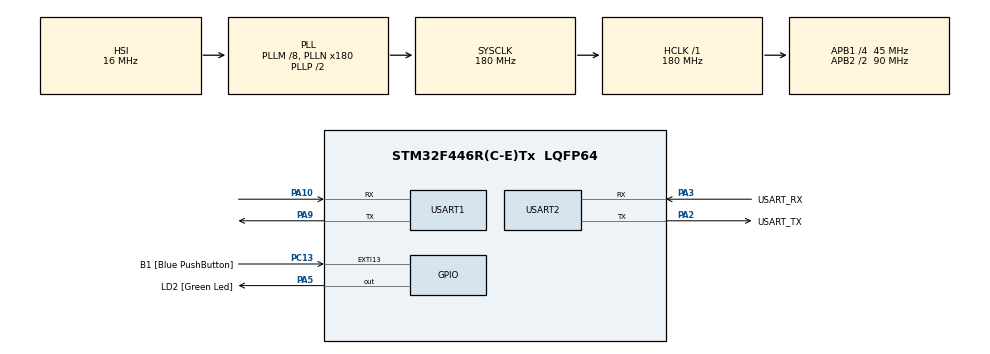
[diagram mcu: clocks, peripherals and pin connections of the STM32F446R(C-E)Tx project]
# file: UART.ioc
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Dma.Request0=USART1_RX
Dma.Request1=USART1_TX
Dma.Request2=USART2_RX
Dma.Request3=USART2_TX
Dma.USART1_RX.0.Direction=DMA_PERIPH_TO_MEMORY
Dma.USART1_RX.0.FIFOMode=DMA_FIFOMODE_DISABLE
Dma.USART1_RX.0.Instance=DMA2_Stream2
Dma.USART1_RX.0.MemDataAlignment=DMA_MDATAALIGN_BYTE
Dma.USART1_RX.0.MemInc=DMA_MINC_ENABLE
Dma.USART1_RX.0.Mode=DMA_CIRCULAR
Dma.USART1_RX.0.PeriphDataAlignment=DMA_PDATAALIGN_BYTE
Dma.USART1_RX.0.PeriphInc=DMA_PINC_DISABLE
Dma.USART1_RX.0.Priority=DMA_PRIORITY_LOW
Dma.USART1_TX.1.Direction=DMA_MEMORY_TO_PERIPH
Dma.USART1_TX.1.FIFOMode=DMA_FIFOMODE_DISABLE
Dma.USART1_TX.1.Instance=DMA2_Stream7
Dma.USART1_TX.1.MemDataAlignment=DMA_MDATAALIGN_BYTE
Dma.USART1_TX.1.MemInc=DMA_MINC_ENABLE
Dma.USART1_TX.1.Mode=DMA_NORMAL
Dma.USART1_TX.1.PeriphDataAlignment=DMA_PDATAALIGN_BYTE
Dma.USART1_TX.1.PeriphInc=DMA_PINC_DISABLE
Dma.USART1_TX.1.Priority=DMA_PRIORITY_LOW
Dma.USART2_RX.2.Direction=DMA_PERIPH_TO_MEMORY
Dma.USART2_RX.2.FIFOMode=DMA_FIFOMODE_DISABLE
Dma.USART2_RX.2.Instance=DMA1_Stream5
Dma.USART2_RX.2.MemDataAlignment=DMA_MDATAALIGN_BYTE
Dma.USART2_RX.2.MemInc=DMA_MINC_ENABLE
Dma.USART2_RX.2.Mode=DMA_CIRCULAR
Dma.USART2_RX.2.PeriphDataAlignment=DMA_PDATAALIGN_BYTE
Dma.USART2_RX.2.PeriphInc=DMA_PINC_DISABLE
Dma.USART2_RX.2.Priority=DMA_PRIORITY_LOW
Dma.USART2_TX.3.Direction=DMA_MEMORY_TO_PERIPH
Dma.USART2_TX.3.FIFOMode=DMA_FIFOMODE_DISABLE
Dma.USART2_TX.3.Instance=DMA1_Stream6
Dma.USART2_TX.3.MemDataAlignment=DMA_MDATAALIGN_BYTE
Dma.USART2_TX.3.MemInc=DMA_MINC_ENABLE
Dma.USART2_TX.3.Mode=DMA_NORMAL
Dma.USART2_TX.3.PeriphDataAlignment=DMA_PDATAALIGN_BYTE
Dma.USART2_TX.3.PeriphInc=DMA_PINC_DISABLE
Dma.USART2_TX.3.Priority=DMA_PRIORITY_LOW
FREERTOS.CountingSemaphores01=uartTxSem,1,Dynamic,NULL,0
FREERTOS.Mutexes01=uartTxMutex,Dynamic,NULL,Available;logMutex,Dynamic,NULL,Available;rtcMutex,Dynamic,NULL,Available;flashMutex,Dynamic,NULL,Available
FREERTOS.Queues01=uartRxQueue,8,FEB_UART_RxQueueMsg_t,0,Dynamic,NULL,NULL
FREERTOS.Tasks01=flashTask,24,2048,StartFlashTask,As weak,NULL,Dynamic,NULL,NULL;uartRxTask,16,2048,StartUARTRxTask,As weak,NULL,Dynamic,NULL,NULL
FREERTOS.configENABLE_FPU=1
FREERTOS.configTOTAL_HEAP_SIZE=51200
Mcu.Family=STM32F4
Mcu.Name=STM32F446R(C-E)Tx
Mcu.Package=LQFP64
NVIC.DMA1_Stream5_IRQn=true\:5\:0\:false\:false\:true\:true\:false\:true\:true
NVIC.DMA1_Stream6_IRQn=true\:5\:0\:false\:false\:true\:true\:false\:true\:true
NVIC.DMA2_Stream2_IRQn=true\:5\:0\:false\:false\:true\:true\:false\:true\:true
NVIC.DMA2_Stream7_IRQn=true\:5\:0\:false\:false\:true\:true\:false\:true\:true
NVIC.PriorityGroup=NVIC_PRIORITYGROUP_4
NVIC.RTC_Alarm_IRQn=true\:5\:0\:false\:false\:true\:true\:true\:true\:true
NVIC.TIM8_TRG_COM_TIM14_IRQn=true\:15\:0\:false\:false\:true\:false\:false\:true\:true
NVIC.TimeBase=TIM8_TRG_COM_TIM14_IRQn
NVIC.TimeBaseIP=TIM14
NVIC.USART1_IRQn=true\:5\:0\:false\:false\:true\:true\:true\:true\:true
NVIC.USART2_IRQn=true\:5\:0\:false\:false\:true\:true\:true\:true\:true
PA10.Mode=Asynchronous
PA10.Signal=USART1_RX
PA13.GPIO_Label=TMS
PA13.Mode=Trace_Asynchronous_SW
PA13.Signal=SYS_JTMS-SWDIO
PA14.GPIO_Label=TCK
PA14.Mode=Trace_Asynchronous_SW
PA14.Signal=SYS_JTCK-SWCLK
PA2.GPIO_Label=USART_TX
PA2.Mode=Asynchronous
PA2.Signal=USART2_TX
PA3.GPIO_Label=USART_RX
PA3.Mode=Asynchronous
PA3.Signal=USART2_RX
PA5.GPIO_Label=LD2 [Green Led]
PA5.Signal=GPIO_Output
PA9.Mode=Asynchronous
PA9.Signal=USART1_TX
PB3.GPIO_Label=SWO
PB3.Mode=Trace_Asynchronous_SW
PB3.Signal=SYS_JTDO-SWO
PC13.GPIO_Label=B1 [Blue PushButton]
PC13.GPIO_ModeDefaultEXTI=GPIO_MODE_IT_FALLING
PC13.Signal=GPXTI13
PC14-OSC32_IN.Mode=LSE-External-Oscillator
PC14-OSC32_IN.Signal=RCC_OSC32_IN
PC15-OSC32_OUT.Mode=LSE-External-Oscillator
PC15-OSC32_OUT.Signal=RCC_OSC32_OUT
ProjectManager.HeapSize=0x200
ProjectManager.StackSize=0x400
ProjectManager.TargetToolchain=CMake
RCC.48MHZClocksFreq_Value=84000000
RCC.AHBFreq_Value=180000000
RCC.APB1CLKDivider=RCC_HCLK_DIV4
RCC.APB1Freq_Value=45000000
RCC.APB1TimFreq_Value=90000000
RCC.APB2CLKDivider=RCC_HCLK_DIV2
RCC.APB2Freq_Value=90000000
RCC.APB2TimFreq_Value=180000000
RCC.CortexFreq_Value=180000000
RCC.FLatency-AdvancedSettings=FLASH_LATENCY_5
RCC.HCLKFreq_Value=180000000
RCC.HSE_VALUE=8000000
RCC.HSI_VALUE=16000000
RCC.PLLM=8
RCC.PLLN=180
RCC.SYSCLKFreq_VALUE=180000000
RCC.SYSCLKSource=RCC_SYSCLKSOURCE_PLLCLK
RCC.USBFreq_Value=180000000
RCC.VCOOutputFreq_Value=360000000
RTC.Alarm=RTC_ALARM_A
USART1.VirtualMode=VM_ASYNC
USART2.VirtualMode=VM_ASYNC
VP_FREERTOS_VS_CMSIS_V2.Mode=CMSIS_V2
VP_RTC_VS_RTC_Activate.Mode=RTC_Enabled
VP_RTC_VS_RTC_Alarm_A_Intern.Mode=Alarm A
VP_RTC_VS_RTC_Calendar.Mode=RTC_Calendar
VP_SYS_VS_tim14.Mode=TIM14
board=NUCLEO-F446RE

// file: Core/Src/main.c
/* USER CODE BEGIN Header */
/**
  ******************************************************************************
  * @file           : main.c
  * @brief          : Main program body
  ******************************************************************************
  * @attention
  *
  * Copyright (c) 2026 STMicroelectronics.
  * All rights reserved.
  *
  * This software is licensed under terms that can be found in the LICENSE file
  * in the root directory of this software component.
  * If no LICENSE file comes with this software, it is provided AS-IS.
  *
  ******************************************************************************
  */
/* USER CODE END Header */
#include "main.h"
#include "cmsis_os.h"
#include "dma.h"
#include "rtc.h"
#include "usart.h"
#include "gpio.h"

void SystemClock_Config(void);
void MX_FREERTOS_Init(void);

int main(void)
{

  /* MCU Configuration--------------------------------------------------------*/

  /* Reset of all peripherals, Initializes the Flash interface and the Systick. */
  HAL_Init();

  /* Configure the system clock */
  SystemClock_Config();

  /* Initialize all configured peripherals */
  MX_GPIO_Init();
  MX_DMA_Init();
  MX_RTC_Init();
  MX_USART1_UART_Init();
  MX_USART2_UART_Init();

  /* Init scheduler */
  osKernelInitialize();  /* Call init function for freertos objects (in cmsis_os2.c) */
  MX_FREERTOS_Init();

  /* Start scheduler */
  osKernelStart();

  /* We should never get here as control is now taken by the scheduler */

  /* Infinite loop */
  while (1)
  {

  }
}

void SystemClock_Config(void)
{
  RCC_OscInitTypeDef RCC_OscInitStruct = {0};
  RCC_ClkInitTypeDef RCC_ClkInitStruct = {0};

  /** Configure the main internal regulator output voltage
  */
  __HAL_RCC_PWR_CLK_ENABLE();
  __HAL_PWR_VOLTAGESCALING_CONFIG(PWR_REGULATOR_VOLTAGE_SCALE1);

  /** Initializes the RCC Oscillators according to the specified parameters
  * in the RCC_OscInitTypeDef structure.
  */
  RCC_OscInitStruct.OscillatorType = RCC_OSCILLATORTYPE_HSI|RCC_OSCILLATORTYPE_LSI;
  RCC_OscInitStruct.LSEState = RCC_LSE_ON;
  RCC_OscInitStruct.HSIState = RCC_HSI_ON;
  RCC_OscInitStruct.HSICalibrationValue = RCC_HSICALIBRATION_DEFAULT;
  RCC_OscInitStruct.LSIState = RCC_LSI_ON;
  RCC_OscInitStruct.PLL.PLLState = RCC_PLL_ON;
  RCC_OscInitStruct.PLL.PLLSource = RCC_PLLSOURCE_HSI;
  RCC_OscInitStruct.PLL.PLLM = 8;
  RCC_OscInitStruct.PLL.PLLN = 180;
  RCC_OscInitStruct.PLL.PLLP = RCC_PLLP_DIV2;
  RCC_OscInitStruct.PLL.PLLQ = 2;
  RCC_OscInitStruct.PLL.PLLR = 2;
  if (HAL_RCC_OscConfig(&RCC_OscInitStruct) != HAL_OK)
  {
    Error_Handler();
  }

  /** Activate the Over-Drive mode
  */
  if (HAL_PWREx_EnableOverDrive() != HAL_OK)
  {
    Error_Handler();
  }

  /** Initializes the CPU, AHB and APB buses clocks
  */
  RCC_ClkInitStruct.ClockType = RCC_CLOCKTYPE_HCLK|RCC_CLOCKTYPE_SYSCLK
                              |RCC_CLOCKTYPE_PCLK1|RCC_CLOCKTYPE_PCLK2;
  RCC_ClkInitStruct.SYSCLKSource = RCC_SYSCLKSOURCE_PLLCLK;
  RCC_ClkInitStruct.AHBCLKDivider = RCC_SYSCLK_DIV1;
  RCC_ClkInitStruct.APB1CLKDivider = RCC_HCLK_DIV4;
  RCC_ClkInitStruct.APB2CLKDivider = RCC_HCLK_DIV2;

  if (HAL_RCC_ClockConfig(&RCC_ClkInitStruct, FLASH_LATENCY_5) != HAL_OK)
  {
    Error_Handler();
  }
}

void HAL_TIM_PeriodElapsedCallback(TIM_HandleTypeDef *htim)
{
  if (htim->Instance == TIM14)
  {
    HAL_IncTick();
  }
}

void Error_Handler(void)
{
  __disable_irq();
  while (1)
  {
  }
}

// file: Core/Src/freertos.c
/* USER CODE BEGIN Header */
/**
  ******************************************************************************
  * File Name          : freertos.c
  * Description        : Code for freertos applications
  ******************************************************************************
  * @attention
  *
  * Copyright (c) 2026 STMicroelectronics.
  * All rights reserved.
  *
  * This software is licensed under terms that can be found in the LICENSE file
  * in the root directory of this software component.
  * If no LICENSE file comes with this software, it is provided AS-IS.
  *
  ******************************************************************************
  */
/* USER CODE END Header */

#include "FreeRTOS.h"
#include "task.h"
#include "main.h"
#include "cmsis_os.h"

/* USER CODE BEGIN Includes */
#include "flash_benchmark.h"
#include "feb_uart.h"
#include "feb_rtos_utils.h"
/* USER CODE END Includes */

/* Definitions for flashTask */
osThreadId_t flashTaskHandle;
const osThreadAttr_t flashTask_attributes = {
  .name = "flashTask",
  .stack_size = 2048 * 4,
  .priority = (osPriority_t) osPriorityNormal,
};
/* Definitions for uartRxTask */
osThreadId_t uartRxTaskHandle;
const osThreadAttr_t uartRxTask_attributes = {
  .name = "uartRxTask",
  .stack_size = 2048 * 4,
  .priority = (osPriority_t) osPriorityBelowNormal,
};
/* Definitions for uartRxQueue */
osMessageQueueId_t uartRxQueueHandle;
const osMessageQueueAttr_t uartRxQueue_attributes = {
  .name = "uartRxQueue"
};
/* Definitions for uartTxMutex */
osMutexId_t uartTxMutexHandle;
const osMutexAttr_t uartTxMutex_attributes = {
  .name = "uartTxMutex"
};
/* Definitions for logMutex */
osMutexId_t logMutexHandle;
const osMutexAttr_t logMutex_attributes = {
  .name = "logMutex"
};
/* Definitions for rtcMutex */
osMutexId_t rtcMutexHandle;
const osMutexAttr_t rtcMutex_attributes = {
  .name = "rtcMutex"
};
/* Definitions for flashMutex */
osMutexId_t flashMutexHandle;
const osMutexAttr_t flashMutex_attributes = {
  .name = "flashMutex"
};
/* Definitions for uartTxSem */
osSemaphoreId_t uartTxSemHandle;
const osSemaphoreAttr_t uartTxSem_attributes = {
  .name = "uartTxSem"
};

void StartFlashTask(void *argument);
void StartUARTRxTask(void *argument);

void MX_FREERTOS_Init(void); /* (MISRA C 2004 rule 8.1) */

void MX_FREERTOS_Init(void) {
  /* Create the mutex(es) */
  /* creation of uartTxMutex */
  uartTxMutexHandle = osMutexNew(&uartTxMutex_attributes);

  /* creation of logMutex */
  logMutexHandle = osMutexNew(&logMutex_attributes);

  /* creation of rtcMutex */
  rtcMutexHandle = osMutexNew(&rtcMutex_attributes);

  /* creation of flashMutex */
  flashMutexHandle = osMutexNew(&flashMutex_attributes);

  /* Create the semaphores(s) */
  /* creation of uartTxSem */
  uartTxSemHandle = osSemaphoreNew(1, 0, &uartTxSem_attributes);

  /* Create the queue(s) */
  /* creation of uartRxQueue */
  uartRxQueueHandle = osMessageQueueNew (8, sizeof(FEB_UART_RxQueueMsg_t), &uartRxQueue_attributes);

  /* Create the thread(s) */
  /* creation of flashTask */
  flashTaskHandle = osThreadNew(StartFlashTask, NULL, &flashTask_attributes);

  /* creation of uartRxTask */
  uartRxTaskHandle = osThreadNew(StartUARTRxTask, NULL, &uartRxTask_attributes);

  /* USER CODE BEGIN RTOS_THREADS */
  /* Validate all RTOS object creations - fail fast on any NULL */
  REQUIRE_RTOS_HANDLE(uartTxMutexHandle);
  REQUIRE_RTOS_HANDLE(logMutexHandle);
  REQUIRE_RTOS_HANDLE(rtcMutexHandle);
  REQUIRE_RTOS_HANDLE(flashMutexHandle);
  REQUIRE_RTOS_HANDLE(uartTxSemHandle);
  REQUIRE_RTOS_HANDLE(uartRxQueueHandle);
  REQUIRE_RTOS_HANDLE(flashTaskHandle);
  REQUIRE_RTOS_HANDLE(uartRxTaskHandle);
  /* USER CODE END RTOS_THREADS */

}

__weak void StartFlashTask(void *argument)
{
  /* USER CODE BEGIN StartFlashTask */
  FlashBench_TaskEntry(argument);
  /* USER CODE END StartFlashTask */
}

__weak void StartUARTRxTask(void *argument)
{
  for(;;)
  {
    osDelay(1);
  }
}
